# nrf54h20_enga_application register map
Vendor: Nordic Semiconductor; Series: nRF54h; File version: 1
CPU: CM33 r0p4, little endian, MPU, FPU, 3 interrupt priority bits, 480 interrupts, 4 SAU regions
Registers are 32-bit, read-write, reset 0x0 unless marked. A register's access mark holds for its fields unless they carry their own. Offsets are from the block's base; [hi:lo] are bit positions; lines under a group give offsets from that group; {n}, {i} and the like mark numbered series; 'fields as' and 'values as' point back to an identical list.

## GLOBAL_CAN_NS — Controller Area Network 0
Base 0x4F8D8000
Same registers: GLOBAL_CAN_S 0x5F8D8000
0x00 TASKS_START wo — Start the CAN peripheral.
  [0] TASKS_START
    1=Trigger task
0x04 TASKS_STOPREQ wo — Request to stop the CAN peripheral
  [0] TASKS_STOPREQ
    1=Trigger task
0x08 TASKS_STOP wo — Stop the CAN peripheral
  [0] TASKS_STOP
    1=Trigger task
{0x100+4i} EVENTS_CORE[{i}] (i=0..1) — Description collection: Event indicating that interrupt n triggered at CAN core
  [0] EVENTS_CORE — Event indicating that interrupt n triggered at CAN core
    0=NotGenerated (Event not generated); 1=Generated (Event generated)
0x108 EVENTS_DMU — Event indicating that interrupt triggered at CAN DMU
  [0] EVENTS_DMU
    values as EVENTS_CORE[0].EVENTS_CORE
0x10C EVENTS_DMA — Event indicating that interrupt triggered at CAN DMA
  [0] EVENTS_DMA
    values as EVENTS_CORE[0].EVENTS_CORE
0x110 EVENTS_READYFORSTOP — Event indicating that the CAN is ready to be stopped
  [0] EVENTS_READYFORSTOP
    values as EVENTS_CORE[0].EVENTS_CORE
0x200 SHORTS — Shortcuts between local events and tasks
  [0] READYFORSTOP_STOP — Shortcut between event READYFORSTOP and task STOP
    0=Disabled (Disable shortcut); 1=Enabled (Enable shortcut)
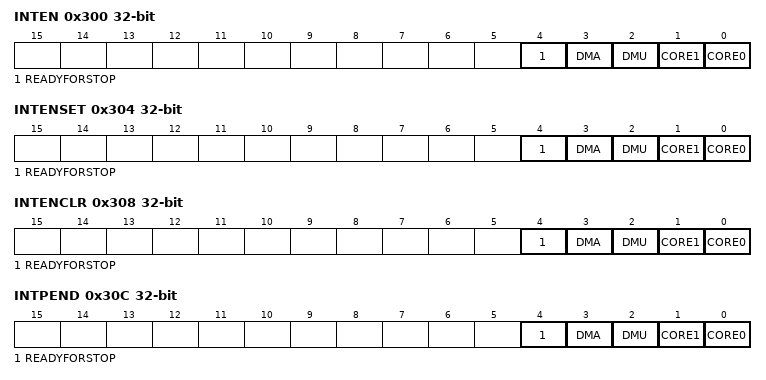
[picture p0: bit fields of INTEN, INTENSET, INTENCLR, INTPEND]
0x300 INTEN — Enable or disable interrupt
  [all] fields
    0=Disabled; 1=Enabled
  [4] READYFORSTOP — Enable or disable interrupt for event READYFORSTOP
  [3] DMA — Enable or disable interrupt for event DMA
  [2] DMU — Enable or disable interrupt for event DMU
  [1] CORE1 — Enable or disable interrupt for event CORE[1]
  [0] CORE0 — Enable or disable interrupt for event CORE[0]
0x304 INTENSET — Enable interrupt
  [all] fields
    on read: 0=Disabled (Read: Disabled); 1=Enabled (Read: Enabled) | on write: 1=Set (Enable)
  [4] READYFORSTOP — Write '1' to enable interrupt for event READYFORSTOP
  [3] DMA — Write '1' to enable interrupt for event DMA
  [2] DMU — Write '1' to enable interrupt for event DMU
  [1] CORE1 — Write '1' to enable interrupt for event CORE[1]
  [0] CORE0 — Write '1' to enable interrupt for event CORE[0]
0x308 INTENCLR — Disable interrupt
  [all] fields
    on read: 0=Disabled (Read: Disabled); 1=Enabled (Read: Enabled) | on write: 1=Clear (Disable)
  [4] READYFORSTOP — Write '1' to disable interrupt for event READYFORSTOP
  [3] DMA — Write '1' to disable interrupt for event DMA
  [2] DMU — Write '1' to disable interrupt for event DMU
  [1] CORE1 — Write '1' to disable interrupt for event CORE[1]
  [0] CORE0 — Write '1' to disable interrupt for event CORE[0]
0x30C INTPEND ro — Pending interrupts
  [all] fields
    on read: 0=NotPending (Read: Not pending); 1=Pending (Read: Pending)
  [4] READYFORSTOP — Read pending status of interrupt for event READYFORSTOP
  [3] DMA — Read pending status of interrupt for event DMA
  [2] DMU — Read pending status of interrupt for event DMU
  [1] CORE1 — Read pending status of interrupt for event CORE[1]
  [0] CORE0 — Read pending status of interrupt for event CORE[0]

## GLOBAL_DPPIC120_NS — Distributed programmable peripheral interconnect controller 0
Base 0x4F8E1000
Same registers: GLOBAL_DPPIC130_NS 0x4F922000, GLOBAL_DPPIC131_NS 0x4F981000, GLOBAL_DPPIC132_NS 0x4F991000, GLOBAL_DPPIC133_NS 0x4F9A1000, GLOBAL_DPPIC134_NS 0x4F9B1000, GLOBAL_DPPIC135_NS 0x4F9C1000, GLOBAL_DPPIC136_NS 0x4F9D1000, GLOBAL_DPPIC120_S 0x5F8E1000, GLOBAL_DPPIC130_S 0x5F922000, GLOBAL_DPPIC131_S 0x5F981000, GLOBAL_DPPIC132_S 0x5F991000, GLOBAL_DPPIC133_S 0x5F9A1000, GLOBAL_DPPIC134_S 0x5F9B1000, GLOBAL_DPPIC135_S 0x5F9C1000, GLOBAL_DPPIC136_S 0x5F9D1000
{0x0+8i} TASKS_CHG[{i}] (i=0..1) group — Channel group tasks
  0x00 EN wo — Description cluster: Enable channel group n
    [0] EN — Enable channel group n
      1=Trigger task
  0x04 DIS wo — Description cluster: Disable channel group n
    [0] DIS — Disable channel group n
      1=Trigger task
{0x80+8i} SUBSCRIBE_CHG[{i}] (i=0..1) group — Subscribe configuration for tasks
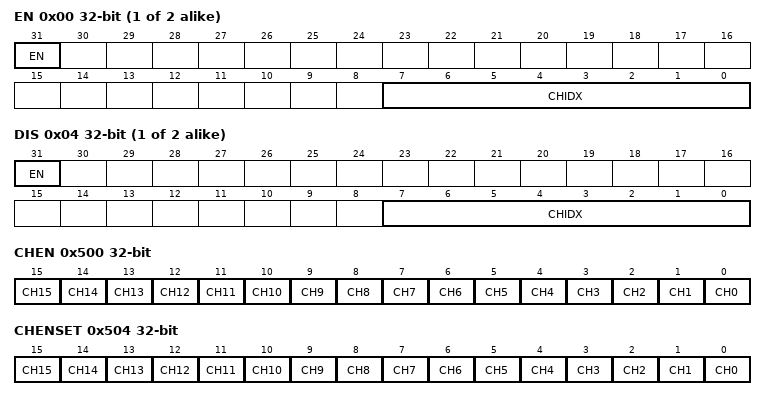
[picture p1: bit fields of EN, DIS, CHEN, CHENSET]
  0x00 EN — Description cluster: Subscribe configuration for task CHG[n].EN
    [31] EN
      0=Disabled (Disable subscription); 1=Enabled (Enable subscription)
    [7:0] CHIDX — DPPI channel that task CHG[n].EN will subscribe to
  0x04 DIS — Description cluster: Subscribe configuration for task CHG[n].DIS
    [31] EN
      values as SUBSCRIBE_CHG[0].EN.EN
    [7:0] CHIDX — DPPI channel that task CHG[n].DIS will subscribe to
0x500 CHEN — Channel enable register
  [all] fields
    0=Disabled (Disable channel); 1=Enabled (Enable channel)
  [n] CH{n} (n=0..15) — Enable or disable channel {n}
0x504 CHENSET write-1-sets — Channel enable set register
  [all] fields
    on read: 0=Disabled (Read: Channel disabled); 1=Enabled (Read: Channel enabled) | on write: 1=Set (Write: Enable channel)
  [n] CH{n} (n=0..15) — Channel {n} enable set register. Writing 0 has no effect.
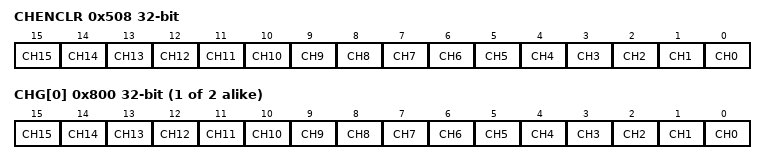
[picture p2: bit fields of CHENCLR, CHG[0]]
0x508 CHENCLR write-1-clears — Channel enable clear register
  [all] fields
    on read: 0=Disabled (Read: Channel disabled); 1=Enabled (Read: Channel enabled) | on write: 1=Clear (Write: Disable channel)
  [n] CH{n} (n=0..15) — Channel {n} enable clear register. Writing 0 has no effect.
{0x800+4i} CHG[{i}] (i=0..1) — Description collection: Channel group n Note: Writes to this register are ignored if either SUBSCRIBE_CHG[n].EN or SUBSCRIBE_CHG[n].DIS is enabled
  [all] fields
    0=Excluded; 1=Included
  [n] CH{n} (n=0..15) — Include or exclude channel {n}

## GLOBAL_TEMP_NS — Temperature Sensor 0
Base 0x4F984000
Same registers: GLOBAL_TEMP_S 0x5F984000
0x00 TASKS_START wo — Start temperature measurement
  [0] TASKS_START
    1=Trigger task
0x04 TASKS_STOP wo — Stop temperature measurement
  [0] TASKS_STOP
    1=Trigger task
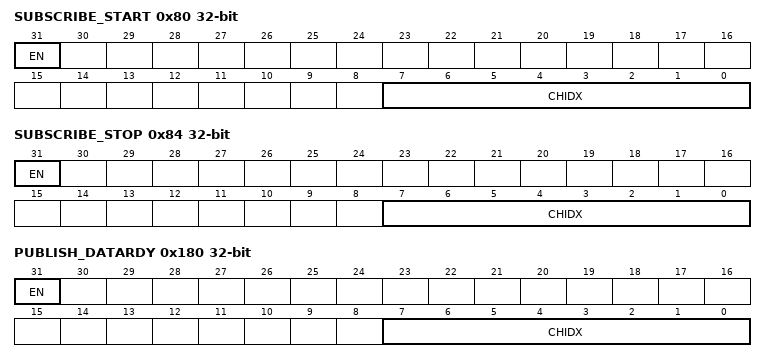
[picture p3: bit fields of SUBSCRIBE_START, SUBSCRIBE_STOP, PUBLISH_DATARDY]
0x80 SUBSCRIBE_START — Subscribe configuration for task START
  [31] EN
    0=Disabled (Disable subscription); 1=Enabled (Enable subscription)
  [7:0] CHIDX — DPPI channel that task START will subscribe to
0x84 SUBSCRIBE_STOP — Subscribe configuration for task STOP
  [31] EN
    values as SUBSCRIBE_START.EN
  [7:0] CHIDX — DPPI channel that task STOP will subscribe to
0x100 EVENTS_DATARDY — Temperature measurement complete, data ready
  [0] EVENTS_DATARDY
    0=NotGenerated (Event not generated); 1=Generated (Event generated)
0x180 PUBLISH_DATARDY — Publish configuration for event DATARDY
  [31] EN
    0=Disabled (Disable publishing); 1=Enabled (Enable publishing)
  [7:0] CHIDX — DPPI channel that event DATARDY will publish to
0x304 INTENSET — Enable interrupt
  [0] DATARDY — Write '1' to enable interrupt for event DATARDY
    on read: 0=Disabled (Read: Disabled); 1=Enabled (Read: Enabled) | on write: 1=Set (Enable)
0x308 INTENCLR — Disable interrupt
  [0] DATARDY — Write '1' to disable interrupt for event DATARDY
    on read: 0=Disabled (Read: Disabled); 1=Enabled (Read: Enabled) | on write: 1=Clear (Disable)
0x508 TEMP ro — Temperature in degC (0.25deg steps)
0x520 A0 reset 0x2D9 — Slope of 1st piece wise linear function
  [11:0] A0
0x524 A1 reset 0x322 — Slope of 2nd piece wise linear function
  [11:0] A1
0x528 A2 reset 0x355 — Slope of 3rd piece wise linear function
  [11:0] A2
0x52C A3 reset 0x3DF — Slope of 4th piece wise linear function
  [11:0] A3
0x530 A4 reset 0x44E — Slope of 5th piece wise linear function
  [11:0] A4
0x534 A5 reset 0x4B7 — Slope of 6th piece wise linear function
  [11:0] A5
0x538 A6 reset 0x4B7 — Slope of 7th piece wise linear function
  [11:0] A6
0x540 B0 reset 0xFC7 — y-intercept of 1st piece wise linear function
  [11:0] B0
0x544 B1 reset 0xF71 — y-intercept of 2nd piece wise linear function
  [11:0] B1
0x548 B2 reset 0xF6C — y-intercept of 3rd piece wise linear function
  [11:0] B2
0x54C B3 reset 0xFCB — y-intercept of 4th piece wise linear function
  [11:0] B3
0x550 B4 reset 0x4B — y-intercept of 5th piece wise linear function
  [11:0] B4
0x554 B5 reset 0xF6 — y-intercept of 6th piece wise linear function
  [11:0] B5
0x558 B6 reset 0xF6 — y-intercept of 7th piece wise linear function
  [11:0] B6
0x560 T0 reset 0xE1 — End point of 1st piece wise linear function
  [7:0] T0
0x564 T1 reset 0xF9 — End point of 2nd piece wise linear function
  [7:0] T1
0x568 T2 reset 0x10 — End point of 3rd piece wise linear function
  [7:0] T2
0x56C T3 reset 0x26 — End point of 4th piece wise linear function
  [7:0] T3
0x570 T4 reset 0x3F — End point of 5th piece wise linear function
  [7:0] T4
0x574 T5 reset 0x78 — End point of 6th piece wise linear function
  [7:0] T5
